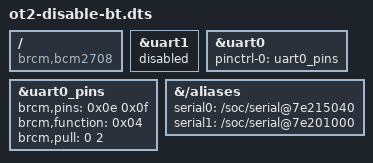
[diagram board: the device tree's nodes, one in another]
/dts-v1/;
/plugin/;

/* Disable Bluetooth and restore UART0/ttyAMA0 over GPIOs 14 & 15.
   To disable the systemd service that initialises the modem so it doesn't use
   the UART:

       sudo systemctl disable hciuart
*/

/{
	compatible = "brcm,bcm2708";

	fragment@0 {
		target = <&uart1>;
		__overlay__ {
			status = "disabled";
		};
	};

	fragment@1 {
		target = <&uart0>;
		__overlay__ {
			pinctrl-names = "default";
			pinctrl-0 = <&uart0_pins>;
			status = "okay";
		};
	};

	fragment@2 {
		target = <&uart0_pins>;
		__overlay__ {
			brcm,pins = <0x0e 0x0f>;
			brcm,function = <0x04>;
			brcm,pull = <0 2>;
			linux,phandle = <0x52>;
			phandle = <0x52>;
		};
	};

	fragment@3 {
		target-path = "/aliases";
		__overlay__ {
			serial0 = "/soc/serial@7e215040";
			serial1 = "/soc/serial@7e201000";
		};
	};
};
